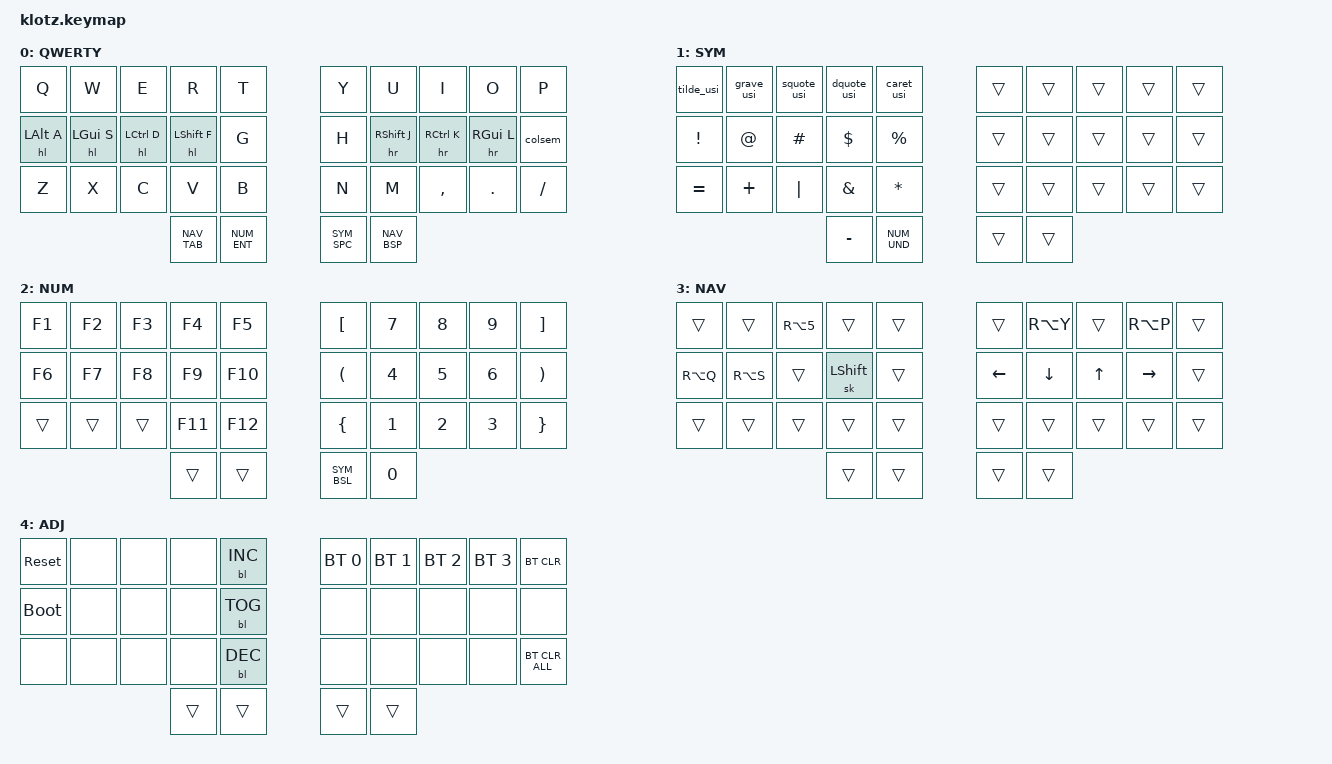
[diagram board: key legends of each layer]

//              █         ██        ▄▀▀▀▀▀▀▀▀▀▀█▀▀▀▀▀▀▀▀█▀▀▀▀▀▀▀▀▀▀█
//              █        █ █      ▄▀            ▀▄      █         █
//              █       █  █    ▄▀                ▀▄    █        █
//              █      █   █   █                    █   █       █
//              █     █    █   █                    █   █      █
//              █    █     █   █                    █   █  ▀▀▀█▀▀▀▀
//              █   █ █    █   █                    █   █    █
//              █  █   █   █   █                    █   █   █
//              █ █     █  █    ▀▄                ▄▀    █  █
//              ██       █ █      ▀▄            ▄▀      █ █
//              █         ██▄▄▄▄▄▄▄▄█▄▄▄▄▄▄▄▄▄▄▀        ██▄▄▄▄▄▄▄▄▄▄
//
//▄▄▄▄▄▄▄▄▄▄▄▄▄▄▄▄▄▄▄▄▄▄▄▄▄▄▄▄▄▄▄▄▄▄▄▄▄▄▄▄▄▄▄▄▄▄▄▄▄▄▄▄▄▄▄▄▄▄▄▄▄▄▄▄▄▄▄▄▄▄▄▄▄▄▄▄▄▄▄
//
//

/* ╭────┬────┬────┬────┬────╮ ⌄        ⌄ ╭────┬────┬────┬────┬────╮
   │  0 │  1 │  2 │  3 │  4 │ │  ⌁⌁⌁⌁   │ │  5 │  6 │  7 │  8 │  9 │
   ├────┼────┼────┼────┼────┼─╯        ╰─┼────┼────┼────┼────┼────┤
   │ 10 │ 11 │ 12 │ 13 │ 14 │╭───╮  ╭───╮│ 15 │ 16 │ 17 │ 18 │ 19 │
   ├────┼────┼────┼────┼────┤│ROT│  │ROT│├────┼────┼────┼────┼────┤
   │ 20 │ 21 │ 22 │ 23 │ 24 │╰───╯  ╰───╯│ 25 │ 26 │ 27 │ 28 │ 29 │
   ╰────┴────┴─────────┼────┼────╮  ╭────┼────┼────┼────┴────┴────╯
                       │ 30 │ 31 │  │ 32 │ 33 │
                       ╰────┴────╯  ╰────┴────╯ */

#include <behaviors.dtsi>
#include <dt-bindings/zmk/keys.h>
#include <dt-bindings/zmk/bt.h>
#include <dt-bindings/zmk/outputs.h>
#include <dt-bindings/zmk/backlight.h>

#include "headers/keypos/klotz.h"
#include "headers/common_headers.h"

/ {

    keymap {
        compatible = "zmk,keymap";

        /*  ┌───────────────────────────────────────────────────────────┐
            │ q w e r t y                                               │
            └───────────────────────────────────────────────────────────┘
            ╭───────────┬───────────┬───────────┬───────────┬───────────╮ ⌄                    ⌄ ╭───────────┬───────────┬───────────┬───────────┬───────────╮
            │     Q     │     W     │     E     │     R     │     T     │ │       ⌁⌁⌁⌁⌁⌁⌁⌁⌁⌁     │ │     Y     │     U     │     I     │     O     │     P     │
            ├───────────┼───────────┼───────────┼───────────┼───────────┼─╯                    ╰─┼───────────┼───────────┼───────────┼───────────┼───────────┤
            │   A/ALT   │   S/GUI   │  D/CTRL   │  F/SHIFT  │     G     │╭──────────╮╭──────────╮│     H     │  J/SHIFT  │  K/CTRL   │   L/GUI   │   :/ALT   │
            ├───────────┼───────────┼───────────┼───────────┼───────────┤│          ││          │├───────────┼───────────┼───────────┼───────────┼───────────┤
            │     Z     │     X     │     C     │     V     │     B     │╰──────────╯╰──────────╯│     N     │     M     │     ,     │     .     │     /     │
            ╰───────────┴───────────┴───────────┴───────────┼───────────┼───────────╮╭───────────┼───────────┼───────────┴───────────┴───────────┴───────────╯
                                                            │  Tab/NAV  │ Enter/NUM ││ Space/SYM │  Esc/NAV  │
                                                            ╰───────────┴───────────╯╰───────────┴───────────╯ */

        qwerty {
            label = "QWERTY";

            bindings = <
             &kp Q       &kp W       &kp E       &kp R       &kp T                                &kp Y       &kp U       &kp I       &kp O       &kp P
             &hl LALT A  &hl LGUI S  &hl LCTRL D &hl LSHFT F &kp G                                &kp H       &hr RSHFT J &hr RCTRL K &hr RGUI L  &colsem
             &kp Z       &kp X       &kp C       &kp V       &kp B                                &kp N       &kp M       &kp COMMA   &kp DOT     &kp SLASH
                                                             NAV_TAB     NUM_ENT      SYM_SPC     NAV_BSP
            >;
            sensor-bindings = <&inc_dec_kp DOWN UP &inc_dec_kp C_VOL_UP C_VOL_DN>;
        };

        /*  ┌───────────────────────────────────────────────────────────┐
            │ s y m b o l s                                             │
            └───────────────────────────────────────────────────────────┘
            ╭───────────┬───────────┬───────────┬───────────┬───────────╮ ⌄                    ⌄ ╭───────────┬───────────┬───────────┬───────────┬───────────╮
            │     ~     │     `     │     '     │     "     │     ^     │ │     ⌁⌁⌁⌁⌁⌁⌁⌁⌁⌁       │ │           │           │           │           │           │
            ├───────────┼───────────┼───────────┼───────────┼───────────┼─╯                    ╰─┼───────────┼───────────┼───────────┼───────────┼───────────┤
            │     !     │     @     │     #     │     $     │     %     │╭──────────╮╭──────────╮│           │           │           │           │           │
            ├───────────┼───────────┼───────────┼───────────┼───────────┤│          ││          │├───────────┼───────────┼───────────┼───────────┼───────────┤
            │     =     │     +     │     |     │     &     │     *     │╰──────────╯╰──────────╯│           │           │           │           │           │
            ╰───────────┴───────────┴───────────┴───────────┼───────────┼───────────╮╭───────────┼───────────┼───────────┴───────────┴───────────┴───────────╯
                                                            │     -     │   _/NUM   ││           │           │
                                                            ╰───────────┴───────────╯╰───────────┴───────────╯ */
        symbols {
            label = "SYM";

            bindings = <
             &tilde_usi  &grave_usi  &squote_usi &dquote_usi &caret_usi                           &trans      &trans      &trans      &trans      &trans
             &kp EXCL    &kp AT      &kp HASH    &kp DLLR    &kp PRCNT                            &trans      &trans      &trans      &trans      &trans
             &kp EQUAL   &kp PLUS    &kp PIPE    &kp AMPS    &kp STAR                             &trans      &trans      &trans      &trans      &trans
                                                             &kp MINUS    NUM_UND     &trans      &trans
            >;
            sensor-bindings = <&inc_dec_kp LEFT RIGHT &inc_dec_kp DOWN UP>;
        };

        /*  ┌───────────────────────────────────────────────────────────┐
            │ n u m b e r s                                             │
            └───────────────────────────────────────────────────────────┘
            ╭───────────┬───────────┬───────────┬───────────┬───────────╮ ⌄                    ⌄ ╭───────────┬───────────┬───────────┬───────────┬───────────╮
            │    F1     │    F2     │    F3     │    F4     │    F5     │ │     ⌁⌁⌁⌁⌁⌁⌁⌁⌁⌁     │ │     [     │     7     │     8     │     9     │     ]     │
            ├───────────┼───────────┼───────────┼───────────┼───────────┼─╯                    ╰─┼───────────┼───────────┼───────────┼───────────┼───────────┤
            │    F6     │    F7     │    F8     │    F9     │    F10    │╭──────────╮╭──────────╮│     (     │     4     │     5     │     6     │     )     │
            ├───────────┼───────────┼───────────┼───────────┼───────────┤│          ││          │├───────────┼───────────┼───────────┼───────────┼───────────┤
            │           │           │           │    F11    │    F12    │╰──────────╯╰──────────╯│     {     │     1     │     2     │     3     │     }     │
            ╰───────────┴───────────┴───────────┴───────────┼───────────┼───────────╮╭───────────┼───────────┼───────────┴───────────┴───────────┴───────────╯
                                                            │           │           ││     \     │     0     │
                                                            ╰───────────┴───────────╯╰───────────┴───────────╯ */
        numbers {
            label = "NUM";

            bindings = <
             &kp F1      &kp F2      &kp F3      &kp F4      &kp F5                               &kp LBKT    &kp N7      &kp N8      &kp N9      &kp RBKT
             &kp F6      &kp F7      &kp F8      &kp F9      &kp F10                              &kp LPAR    &kp N4      &kp N5      &kp N6      &kp RPAR
             &trans      &trans      &trans      &kp F11     &kp F12                              &kp LBRC    &kp N1      &kp N2      &kp N3      &kp RBRC
                                                             &trans       &trans      SYM_BSL     &kp N0
            >;
            sensor-bindings = <&inc_dec_kp C_VOL_UP C_VOL_DN  &inc_dec_kp LC(A) LC(X)>;
        };

        /*  ┌───────────────────────────────────────────────────────────┐
            │ n a v i g a t i o n                                       │
            └───────────────────────────────────────────────────────────┘
            ╭───────────┬───────────┬───────────┬───────────┬───────────╮ ⌄                    ⌄ ╭───────────┬───────────┬───────────┬───────────┬───────────╮
            │           │           │     €     │           │           │ │     ⌁⌁⌁⌁⌁⌁⌁⌁⌁⌁     │ │           │     Ü     │           │     Ö     │           │
            ├───────────┼───────────┼───────────┼───────────┼───────────┼─╯                    ╰─┼───────────┼───────────┼───────────┼───────────┼───────────┤
            │     Ä     │     ß     │           │  OSM SFT  │           │╭──────────╮╭──────────╮│     ←     │     ↓     │     ↑     │     →     │           │
            ├───────────┼───────────┼───────────┼───────────┼───────────┤│          ││          │├───────────┼───────────┼───────────┼───────────┼───────────┤
            │           │           │           │           │           │╰──────────╯╰──────────╯│           │           │           │           │           │
            ╰───────────┴───────────┴───────────┴───────────┼───────────┼───────────╮╭───────────┼───────────┼───────────┴───────────┴───────────┴───────────╯
                                                            │           │           ││           │           │
                                                            ╰───────────┴───────────╯╰───────────┴───────────╯ */
        navigation {
            label = "NAV";

            bindings = <
             &trans      &trans      &kp RA(N5)  &trans      &trans                               &trans      &kp RA(Y)   &trans      &kp RA(P)   &trans
             &kp RA(Q)   &kp RA(S)   &trans      &sk LSHIFT  &trans                               &kp LEFT    &kp DOWN    &kp UP      &kp RIGHT   &trans
             &trans      &trans      &trans      &trans      &trans                               &trans      &trans      &trans      &trans      &trans
                                                             &trans       &trans      &trans      &trans
            >;
            sensor-bindings = <&inc_dec_kp PG_DN PG_UP  &inc_dec_kp LC(RIGHT) LC(LEFT)>;
        };

        /*  ┌───────────────────────────────────────────────────────────┐
            │ a d j u s t                                               │
            └───────────────────────────────────────────────────────────┘
            ╭───────────┬───────────┬───────────┬───────────┬───────────╮ ⌄                    ⌄ ╭───────────┬───────────┬───────────┬───────────┬───────────╮
            │   Reset   │           │           │Tap. Term ↑│           │ │     ⌁⌁⌁⌁⌁⌁⌁⌁⌁⌁       │ │           │           │           │           │           │
            ├───────────┼───────────┼───────────┼───────────┼───────────┼─╯                    ╰─┼───────────┼───────────┼───────────┼───────────┼───────────┤
            │Bootloader │           │           │Print TapT.│           │╭──────────╮╭──────────╮│     ←     │     ↓     │     ↑     │     →     │           │
            ├───────────┼───────────┼───────────┼───────────┼───────────┤│          ││          │├───────────┼───────────┼───────────┼───────────┼───────────┤
            │Make Keymap│           │           │Tap. Term ↓│           │╰──────────╯╰──────────╯│           │           │           │           │           │
            ╰───────────┴───────────┴───────────┴───────────┼───────────┼───────────╮╭───────────┼───────────┼───────────┴───────────┴───────────┴───────────╯
                                                            │           │           ││           │           │
                                                            ╰───────────┴───────────╯╰───────────┴───────────╯ */
        function {
            label = "ADJ";

            bindings = <
                &sys_reset &none     &none       &none       &bl BL_INC                           &bt BT_SEL 0 &bt BT_SEL 1 &bt BT_SEL 2 &bt BT_SEL 3  &bt BT_CLR
                &bootloader &none    &none       &none       &bl BL_TOG                           &none        &none       &none         &none         &none
                &none      &none     &none       &none       &bl BL_DEC                           &none        &none       &none         &none         &bt BT_CLR_ALL
                                                             &trans      &trans       &trans      &trans
            >;
            sensor-bindings = <&inc_dec_kp UP DOWN  &inc_dec_kp RIGHT LEFT>;
        };
    };
};
